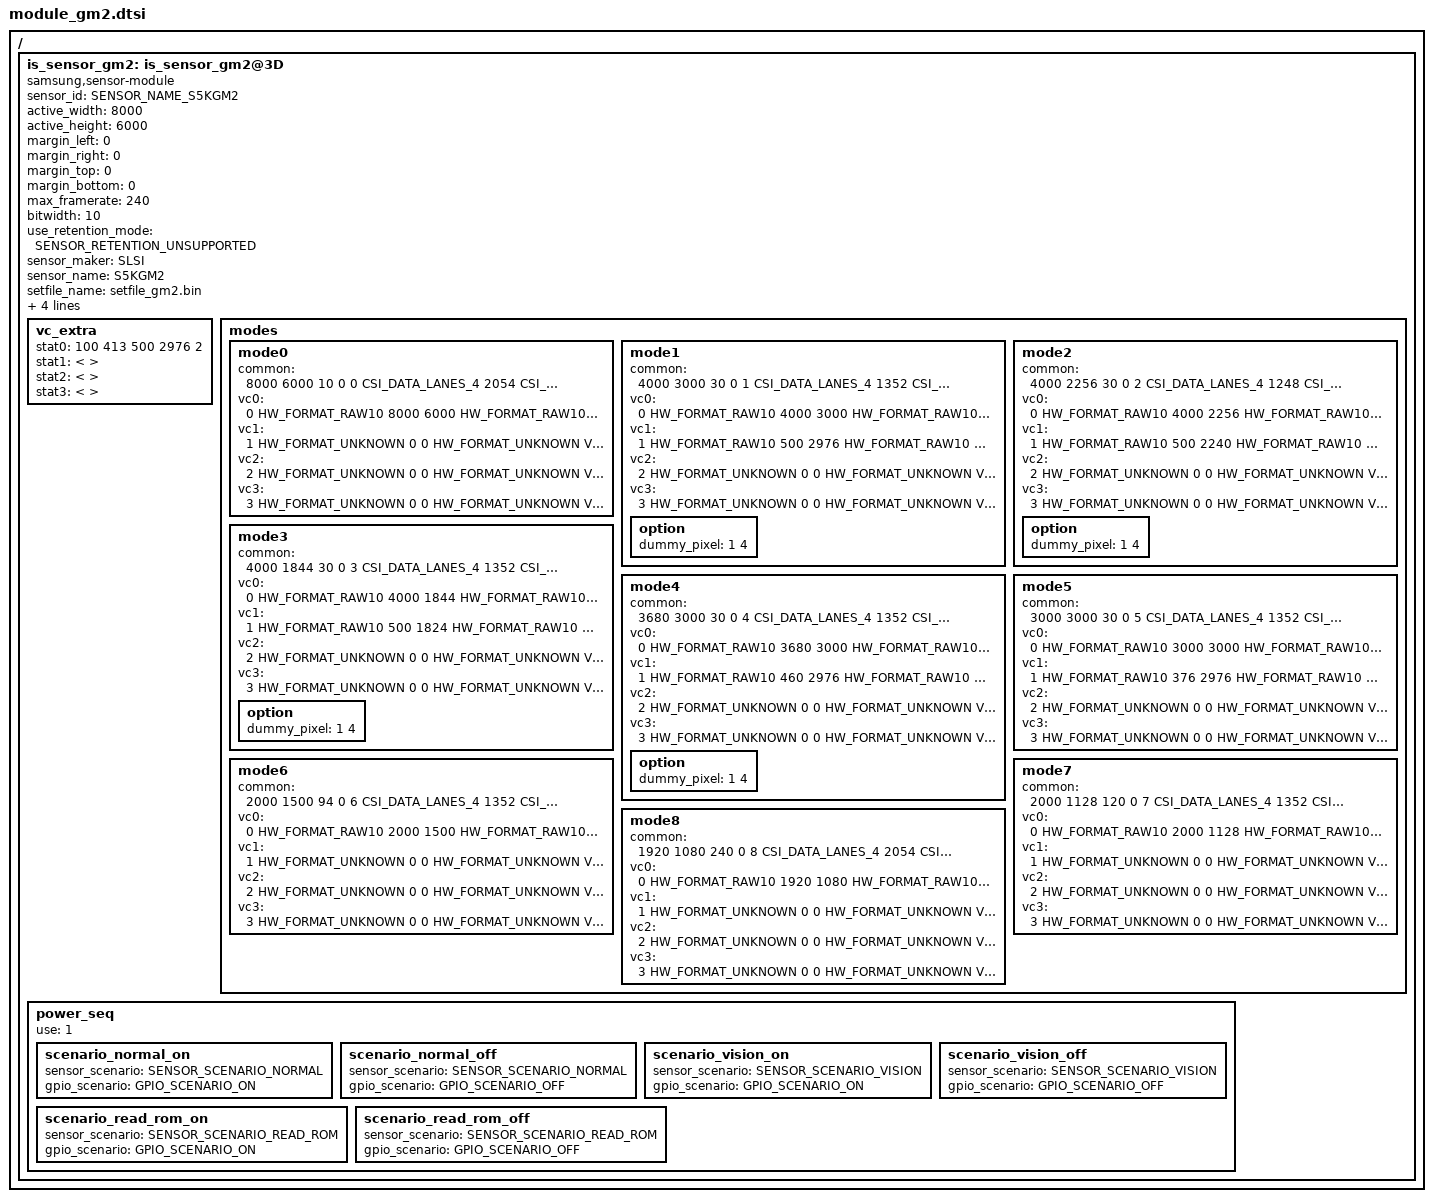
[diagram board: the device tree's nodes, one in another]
/*
 * SAMSUNG EXYNOSxxxx board camera device tree source
 *
 * Copyright (c) 2019 Samsung Electronics Co., Ltd.
 *		http://www.samsung.com
 *
 * This program is free software; you can redistribute it and/or modify
 * it under the terms of the GNU General Public License version 2 as
 * published by the Free Software Foundation.
 */

#include <dt-bindings/camera/exynos_is_dt.h>

#ifndef USE_VENDOR_PWR_PIN_NAME
#define RCAM_AF_VDD	<>
#define GM2_AVDD		<>
#define GM2_DVDD		<>
#define GM2_IOVDD	<>
#endif

/ {
	fragment@camera {
		target-path = "/";
		__overlay__ {
			is_sensor_gm2: is_sensor_gm2@3D {
				compatible = "samsung,sensor-module";

				/* common */
				sensor_id = <SENSOR_NAME_S5KGM2>;
				active_width = <8000>;
				active_height = <6000>;
				margin_left = <0>;
				margin_right = <0>;
				margin_top = <0>;
				margin_bottom = <0>;
				max_framerate = <240>;
				bitwidth = <10>;
				use_retention_mode = <SENSOR_RETENTION_UNSUPPORTED>;
				sensor_maker = "SLSI";
				sensor_name = "S5KGM2";
				setfile_name = "setfile_gm2.bin";

				rcam_af_vdd-supply = RCAM_AF_VDD;
				gm2_avdd-supply = GM2_AVDD;
				gm2_dvdd-supply = GM2_DVDD;
				gm2_iovdd-supply = GM2_IOVDD;
				
				status = "okay";

				vc_extra {
					/* ex) statX = <stat_type, sensor_mode, max_width, max_height, max_element> */
					stat0 = </* VC_STAT_TYPE_TAIL_FOR_SW_PDAF */ 100 /* VC_SENSOR_MODE_SUPER_PD_5_TAIL */ 413 500 2976 2>;	/* VC_BUF_DATA_TYPE_SENSOR_STAT1 */
					stat1 = </* not avaliable */>;									/* VC_BUF_DATA_TYPE_GENERAL_STAT1 */
					stat2 = </* not avaliable */>;									/* VC_BUF_DATA_TYPE_SENSOR_STAT2 */
					stat3 = </* not avaliable */>;									/* VC_BUF_DATA_TYPE_GENERAL_STAT2 */
				};

				/*
				 * [Mode Information]
				 *
				 * Reference File : S5KGM2SP_EVT0_Setfile_Ver2.4_200330.xlsx
				 * Update Data    : 2020-04-02
				 * Author         : kmin.kim
				 *
				 * - Remosaic Full For Single Still Remosaic Capture -
				 *    [  0 ] FULL : Remosaic Full 8000x6000 10fps  2054Mbps     : Single Still Remosaic Capture (4:3)
				 *
				 * - 2x2 BIN For Still Preview / Capture -
				 *    [  1 ] 2SUM2BIN : 2 Binning Full 4000x3000 30fps  1352MBps  : Single Still Preview/Capture (4:3)
				 *    [  2 ] 2SUM2BIN : 2 Binning Crop 4000X2256 30fps  1248MBps  : Single Still Preview/Capture (16:9)
				 *    [  3 ] 2SUM2BIN : 2 Binning Crop 4000X1844 30fps  1352MBps  : Single Still Preview/Capture (19.5:9)
				 *    [  4 ] 2SUM2BIN : 2 Binning Crop 3680X3000 30fps  1352MBps  : MMS (11:9)
				 *    [  5 ] 2SUM2BIN : 2 Binning Crop 3000X3000 30fps  1352MBps  : Single Still Preview/Capture (1:1)
				 *    [  6 ] 4SUM4BIN : 4 Binning Full 2000X1500 94fps  1352MBps  : Fast-AE (2000x1500@94fps)
				 *    [  7 ] 4SUM4BIN : 4 Binning Crop 2000X1128 120fps 1352MBps  : SlowMotion (1280x720@120fps)
				 *    [  8 ] 4SUM4BIN : 4 Binning Crop 1920X1080 240fps 2054Mbps  : SlowMotion (1280x720@240fps)
				 *
				 */

				/* sensor modes */
				modes {
						/* common = <width, height, fps, settle, mode, lane, speed, interleave, lrte, pd_mode> */
						/* vcX = <map, hwformat, width, height, hwformat, type, width, height> */
					/* Remosaic Full For Single Still Remosaic Capture */
					mode0 {
						common = <8000 6000 10 0 0 CSI_DATA_LANES_4 2054 CSI_MODE_VC_ONLY LRTE_DISABLE PD_NONE EX_NONE>;
						vc0 = </* in */ 0 HW_FORMAT_RAW10 8000 6000	/* out */ HW_FORMAT_RAW10 VC_NOTHING 0 0>;
						vc1 = </* in */ 1 HW_FORMAT_UNKNOWN 0 0		/* out */ HW_FORMAT_UNKNOWN VC_NOTHING 0 0>;
						vc2 = </* in */ 2 HW_FORMAT_UNKNOWN 0 0		/* out */ HW_FORMAT_UNKNOWN VC_NOTHING 0 0>;
						vc3 = </* in */ 3 HW_FORMAT_UNKNOWN 0 0		/* out */ HW_FORMAT_UNKNOWN VC_NOTHING 0 0>;
					};

					/* 2SUM2BIN Full For Single Still Preview / Capture */
					mode1 {
						common = <4000 3000 30 0 1 CSI_DATA_LANES_4 1352 CSI_MODE_VC_ONLY LRTE_DISABLE PD_MSPD_TAIL EX_NONE>;
						vc0 = </* in */ 0 HW_FORMAT_RAW10 4000 3000	/* out */ HW_FORMAT_RAW10 VC_NOTHING 4000 3000>;
						vc1 = </* in */ 1 HW_FORMAT_RAW10 500 2976	/* out */ HW_FORMAT_RAW10 VC_TAILPDAF 500 2976>; /* dummy 4 pixels in a line for 16byte DAM align */
						vc2 = </* in */ 2 HW_FORMAT_UNKNOWN 0 0		/* out */ HW_FORMAT_UNKNOWN VC_NOTHING 0 0>;
						vc3 = </* in */ 3 HW_FORMAT_UNKNOWN 0 0		/* out */ HW_FORMAT_UNKNOWN VC_NOTHING 0 0>;
						option { dummy_pixel = <1 4>; };
					};

					/* 2SUM2BIN Crop For Single Still Preview / Capture */
					mode2 {
						common = <4000 2256 30 0 2 CSI_DATA_LANES_4 1248 CSI_MODE_VC_ONLY LRTE_DISABLE PD_MSPD_TAIL EX_NONE>;
						vc0 = </* in */ 0 HW_FORMAT_RAW10 4000 2256 	/* out */ HW_FORMAT_RAW10 VC_NOTHING 4000 2256>;
						vc1 = </* in */ 1 HW_FORMAT_RAW10 500 2240   	/* out */ HW_FORMAT_RAW10 VC_TAILPDAF 500 2240>; /* dummy 4 pixels in a line for 16byte DAM align */
						vc2 = </* in */ 2 HW_FORMAT_UNKNOWN 0 0     	/* out */ HW_FORMAT_UNKNOWN VC_NOTHING 0 0>;
						vc3 = </* in */ 3 HW_FORMAT_UNKNOWN 0 0			/* out */ HW_FORMAT_UNKNOWN VC_NOTHING 0 0>;
						option { dummy_pixel = <1 4>; };
					};

					/* 2SUM2BIN Crop For Single Still Preview / Capture */
					mode3{
						common = <4000 1844 30 0 3 CSI_DATA_LANES_4 1352 CSI_MODE_VC_ONLY LRTE_DISABLE PD_MSPD_TAIL EX_NONE>;
						vc0 = </* in */ 0 HW_FORMAT_RAW10 4000 1844	/* out */ HW_FORMAT_RAW10 VC_NOTHING 4000 1844>;
						vc1 = </* in */ 1 HW_FORMAT_RAW10 500 1824	/* out */ HW_FORMAT_RAW10 VC_TAILPDAF 500 1824>; /* dummy 4 pixels in a line for 16byte DAM align */
						vc2 = </* in */ 2 HW_FORMAT_UNKNOWN 0 0		/* out */ HW_FORMAT_UNKNOWN VC_NOTHING 0 0>;
						vc3 = </* in */ 3 HW_FORMAT_UNKNOWN 0 0		/* out */ HW_FORMAT_UNKNOWN VC_NOTHING 0 0>;
						option { dummy_pixel = <1 4>; };
					};

					/* 2SUM2BIN Crop For Single Still Preview / Capture */
					mode4 {
						common = <3680 3000 30 0 4 CSI_DATA_LANES_4 1352 CSI_MODE_VC_ONLY LRTE_DISABLE PD_MSPD_TAIL EX_NONE>;
						vc0 = </* in */ 0 HW_FORMAT_RAW10 3680 3000	/* out */ HW_FORMAT_RAW10 VC_NOTHING 3680 3000>;
						vc1 = </* in */ 1 HW_FORMAT_RAW10 460 2976	/* out */ HW_FORMAT_RAW10 VC_TAILPDAF 460 2976>; /* dummy 4 pixels in a line for 16byte DAM align */
						vc2 = </* in */ 2 HW_FORMAT_UNKNOWN 0 0		/* out */ HW_FORMAT_UNKNOWN VC_NOTHING 0 0>;
						vc3 = </* in */ 3 HW_FORMAT_UNKNOWN 0 0		/* out */ HW_FORMAT_UNKNOWN VC_NOTHING 0 0>;
						option { dummy_pixel = <1 4>; };
					};

					/* 2SUM2BIN Crop For Single Still Preview / Capture */
					mode5 {
						common = <3000 3000 30 0 5 CSI_DATA_LANES_4 1352 CSI_MODE_VC_ONLY LRTE_DISABLE PD_MSPD_TAIL EX_NONE>;
						vc0 = </* in */ 0 HW_FORMAT_RAW10 3000 3000	/* out */ HW_FORMAT_RAW10 VC_NOTHING 3000 3000>;
						vc1 = </* in */ 1 HW_FORMAT_RAW10 376 2976	/* out */ HW_FORMAT_RAW10 VC_TAILPDAF 376 2976>;
						vc2 = </* in */ 2 HW_FORMAT_UNKNOWN 0 0		/* out */ HW_FORMAT_UNKNOWN VC_NOTHING 0 0>;
						vc3 = </* in */ 3 HW_FORMAT_UNKNOWN 0 0		/* out */ HW_FORMAT_UNKNOWN VC_NOTHING 0 0>;
					};

					/* 4SUM4BIN Full For Fast-AE (2000x1500@94fps) */
					mode6 {
						common = <2000 1500 94 0 6 CSI_DATA_LANES_4 1352 CSI_MODE_VC_ONLY LRTE_DISABLE PD_NONE EX_NONE>;
						vc0 = </* in */ 0 HW_FORMAT_RAW10 2000 1500 	/* out */ HW_FORMAT_RAW10 VC_NOTHING 0 0>;
						vc1 = </* in */ 1 HW_FORMAT_UNKNOWN 0 0     	/* out */ HW_FORMAT_UNKNOWN VC_NOTHING 0 0>;
						vc2 = </* in */ 2 HW_FORMAT_UNKNOWN 0 0     	/* out */ HW_FORMAT_UNKNOWN VC_NOTHING 0 0>;
						vc3 = </* in */ 3 HW_FORMAT_UNKNOWN 0 0     	/* out */ HW_FORMAT_UNKNOWN VC_NOTHING 0 0>;
					};

					/* 4SUM4BIN Crop For SlowMotion (2000x1128@120fps) */
					mode7{
						common = <2000 1128 120 0 7 CSI_DATA_LANES_4 1352 CSI_MODE_VC_ONLY LRTE_DISABLE PD_NONE EX_NONE>;
						vc0 = </* in */ 0 HW_FORMAT_RAW10 2000 1128	/* out */ HW_FORMAT_RAW10 VC_NOTHING 0 0>;
						vc1 = </* in */ 1 HW_FORMAT_UNKNOWN 0 0		/* out */ HW_FORMAT_UNKNOWN VC_NOTHING 0 0>;
						vc2 = </* in */ 2 HW_FORMAT_UNKNOWN 0 0		/* out */ HW_FORMAT_UNKNOWN VC_NOTHING 0 0>;
						vc3 = </* in */ 3 HW_FORMAT_UNKNOWN 0 0		/* out */ HW_FORMAT_UNKNOWN VC_NOTHING 0 0>;
					};

					/* 4SUM4BIN Crop For SlowMotion (1920x1080@240fps) */
					mode8 {
						common = <1920 1080 240 0 8 CSI_DATA_LANES_4 2054 CSI_MODE_VC_ONLY LRTE_DISABLE PD_NONE EX_NONE>;
						vc0 = </* in */ 0 HW_FORMAT_RAW10 1920 1080	/* out */ HW_FORMAT_RAW10 VC_NOTHING 0 0>;
						vc1 = </* in */ 1 HW_FORMAT_UNKNOWN 0 0		/* out */ HW_FORMAT_UNKNOWN VC_NOTHING 0 0>;
						vc2 = </* in */ 2 HW_FORMAT_UNKNOWN 0 0		/* out */ HW_FORMAT_UNKNOWN VC_NOTHING 0 0>;
						vc3 = </* in */ 3 HW_FORMAT_UNKNOWN 0 0		/* out */ HW_FORMAT_UNKNOWN VC_NOTHING 0 0>;
					};
				};

				power_seq {
					use = <1>;
					scenario_normal_on {
						sensor_scenario = <SENSOR_SCENARIO_NORMAL>;
						gpio_scenario = <GPIO_SCENARIO_ON>;

						/* A start node number should be over the 10 for reserved number 0~9. */
						/* pname = "name"; pin = <act value dealy voltage>; gpio = <gpx# # 0x1>; */
					};

					scenario_normal_off {
						sensor_scenario = <SENSOR_SCENARIO_NORMAL>;
						gpio_scenario = <GPIO_SCENARIO_OFF>;

						/* A start node number should be over the 10 for reserved number 0~9. */
						/* pname = "name"; pin = <act value dealy voltage>; gpio = <gpx# # 0x1>; */
					};

					scenario_vision_on {
						sensor_scenario = <SENSOR_SCENARIO_VISION>;
						gpio_scenario = <GPIO_SCENARIO_ON>;

						/* A start node number should be over the 10 for reserved number 0~9. */
						/* pname = "name"; pin = <act value dealy voltage>; gpio = <gpx# # 0x1>; */
					};

					scenario_vision_off {
						sensor_scenario = <SENSOR_SCENARIO_VISION>;
						gpio_scenario = <GPIO_SCENARIO_OFF>;

						/* A start node number should be over the 10 for reserved number 0~9. */
						/* pname = "name"; pin = <act value dealy voltage>; gpio = <gpx# # 0x1>; */
					};

					scenario_read_rom_on {
						sensor_scenario = <SENSOR_SCENARIO_READ_ROM>;
						gpio_scenario = <GPIO_SCENARIO_ON>;
					};

					scenario_read_rom_off {
						sensor_scenario = <SENSOR_SCENARIO_READ_ROM>;
						gpio_scenario = <GPIO_SCENARIO_OFF>;
					};
				};
			};
		}; /* end of __overlay__ */
	}; /* end of fragment */
}; /* end of root */
